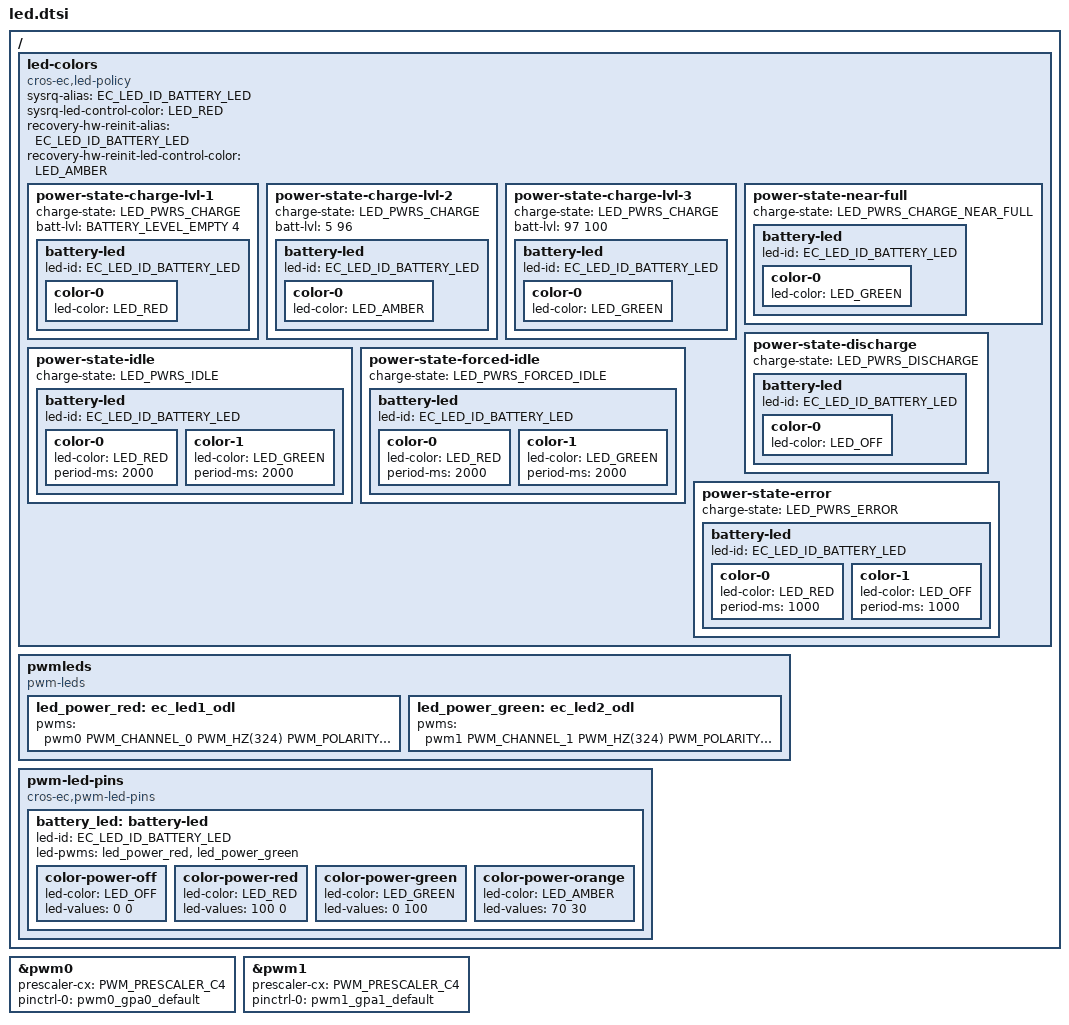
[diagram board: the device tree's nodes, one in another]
/* Copyright 2023 The ChromiumOS Authors
 * Use of this source code is governed by a BSD-style license that can be
 * found in the LICENSE file.
 */
#include <dt-bindings/battery.h>

/ {
	led-colors {
		compatible = "cros-ec,led-policy";

		sysrq-alias = "EC_LED_ID_BATTERY_LED";
		sysrq-led-control-color = "LED_RED";

		recovery-hw-reinit-alias = "EC_LED_ID_BATTERY_LED";
		recovery-hw-reinit-led-control-color = "LED_AMBER";

		power-state-charge-lvl-1 {
			charge-state = "LED_PWRS_CHARGE";

			/* Battery display percent range (>= Empty, <= 4%) */
			batt-lvl = <BATTERY_LEVEL_EMPTY 4>;

			battery-led {
				led-id = "EC_LED_ID_BATTERY_LED";

				color-0 {
					led-color = "LED_RED";
				};
			};
		};

		power-state-charge-lvl-2 {
			charge-state = "LED_PWRS_CHARGE";

			/* Battery display percent range (>= 5%, <= 96%) */
			batt-lvl = <5 96>;

			battery-led {
				led-id = "EC_LED_ID_BATTERY_LED";

				color-0 {
					led-color = "LED_AMBER";
				};
			};
		};

		power-state-charge-lvl-3 {
			charge-state = "LED_PWRS_CHARGE";

			/* Battery display percent range (>= 97) */
			batt-lvl = <97 100>;

			battery-led {
				led-id = "EC_LED_ID_BATTERY_LED";

				color-0 {
					led-color = "LED_GREEN";
				};
			};
		};

		power-state-near-full {
			charge-state = "LED_PWRS_CHARGE_NEAR_FULL";

			battery-led {
				led-id = "EC_LED_ID_BATTERY_LED";

				color-0 {
					led-color = "LED_GREEN";
				};
			};
		};

		power-state-discharge {
			charge-state = "LED_PWRS_DISCHARGE";

			battery-led {
				led-id = "EC_LED_ID_BATTERY_LED";

				color-0 {
					led-color = "LED_OFF";
				};
			};
		};

		power-state-idle {
			charge-state = "LED_PWRS_IDLE";

			battery-led {
				led-id = "EC_LED_ID_BATTERY_LED";

				color-0 {
					led-color = "LED_RED";
					period-ms = <2000>;
				};
				color-1 {
					led-color = "LED_GREEN";
					period-ms = <2000>;
				};
			};
		};

		power-state-forced-idle {
			charge-state = "LED_PWRS_FORCED_IDLE";

			battery-led {
				led-id = "EC_LED_ID_BATTERY_LED";

				color-0 {
					led-color = "LED_RED";
					period-ms = <2000>;
				};
				color-1 {
					led-color = "LED_GREEN";
					period-ms = <2000>;
				};
			};
		};

		power-state-error {
			charge-state = "LED_PWRS_ERROR";

			battery-led {
				led-id = "EC_LED_ID_BATTERY_LED";

				color-0 {
					led-color = "LED_RED";
					period-ms = <1000>;
				};
				color-1 {
					led-color = "LED_OFF";
					period-ms = <1000>;
				};
			};
		};
	};

	pwmleds {
		compatible = "pwm-leds";

		/* NOTE: &pwm number needs same with channel number */
		led_power_red: ec_led1_odl {
			pwms = <&pwm0
				PWM_CHANNEL_0
				PWM_HZ(324)
				PWM_POLARITY_NORMAL>;
		};

		led_power_green: ec_led2_odl {
			pwms = <&pwm1
				PWM_CHANNEL_1
				PWM_HZ(324)
				PWM_POLARITY_NORMAL>;
		};
	};

	pwm-led-pins {
		compatible = "cros-ec,pwm-led-pins";

		battery_led: battery-led {
			led-id = "EC_LED_ID_BATTERY_LED";
			led-pwms = <&led_power_red &led_power_green>;

			color-power-off {
				led-color = "LED_OFF";
				led-values = <0 0>;
			};

			color-power-red {
				led-color = "LED_RED";
				led-values = <100 0>;
			};

			color-power-green {
				led-color = "LED_GREEN";
				led-values = <0 100>;
			};

			color-power-orange {
				led-color = "LED_AMBER";
				led-values = <70 30>;
			};
		};
	};
};

/*
 * LED1
 * Broken, see b/269706760#comment4
 */
&pwm0 {
	status = "okay";
	prescaler-cx = <PWM_PRESCALER_C4>;
	pinctrl-0 = <&pwm0_gpa0_default>;
	pinctrl-names = "default";
};

/* LED2 */
&pwm1 {
	status = "okay";
	prescaler-cx = <PWM_PRESCALER_C4>;
	pinctrl-0 = <&pwm1_gpa1_default>;
	pinctrl-names = "default";
};
